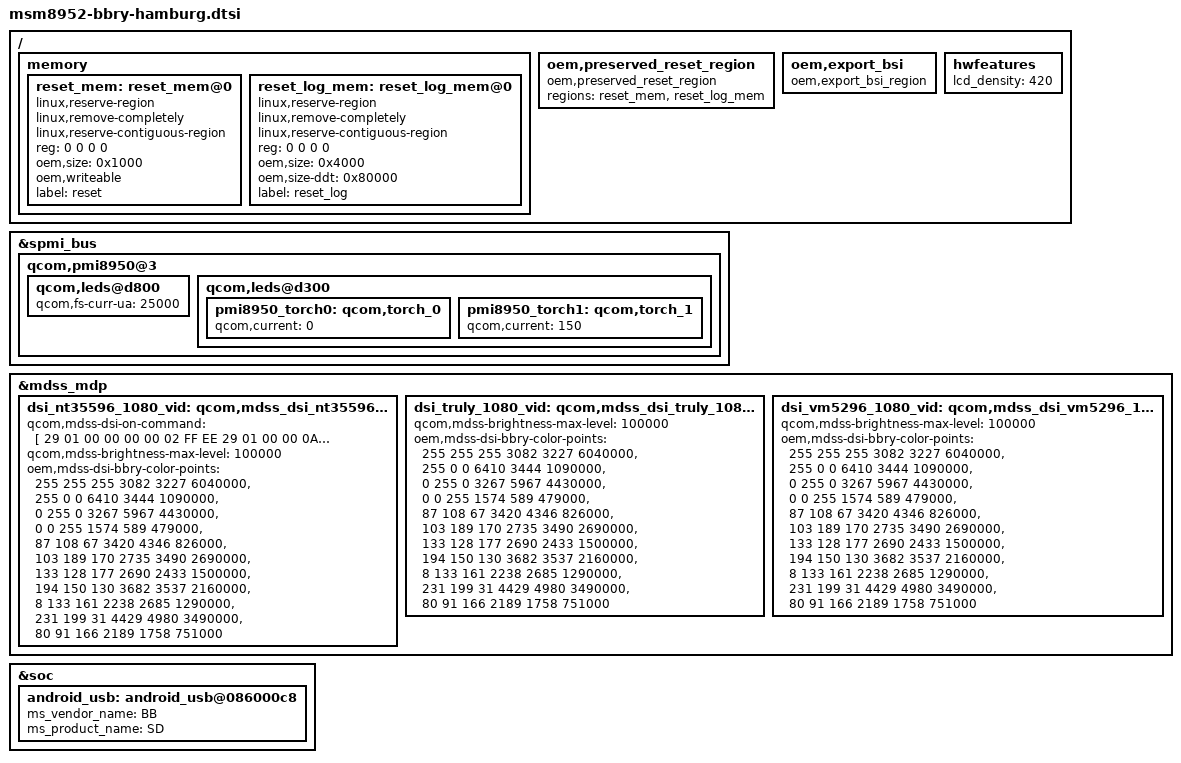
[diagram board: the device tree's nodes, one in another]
/* Copyright (C) 2016 BlackBerry Limited. All rights reserved.
 * Copyright (c) 2014, The Linux Foundation. All rights reserved.
 *
 * This program is free software; you can redistribute it and/or modify
 * it under the terms of the GNU General Public License version 2 and
 * only version 2 as published by the Free Software Foundation.
 *
 * This program is distributed in the hope that it will be useful,
 * but WITHOUT ANY WARRANTY; without even the implied warranty of
 * MERCHANTABILITY or FITNESS FOR A PARTICULAR PURPOSE.  See the
 * GNU General Public License for more details.
 */


/ {
	memory {
		reset_mem: reset_mem@0 {
			linux,reserve-region;
			linux,remove-completely;
			linux,reserve-contiguous-region;
			/*
			 * Bootloader take the address from the oem,size props
			 * and insert it here along with the address
			 */
			reg = <0 0 0 0>;
			oem,size = <0x1000>;
			oem,writeable;
			label = "reset";
		};

		reset_log_mem: reset_log_mem@0 {
			linux,reserve-region;
			linux,remove-completely;
			linux,reserve-contiguous-region;
			/*
			 * Bootloader take the address from the oem,size props
			 * and insert it here along with the address
			 */
			reg = <0 0 0 0>;
			oem,size = <0x4000>;
			/* If ddt is enabled, we reserve more memory */
			oem,size-ddt = <0x80000>;
			label = "reset_log";
		};
	};

	oem,preserved_reset_region {
		compatible = "oem,preserved_reset_region";
		regions = <&reset_mem &reset_log_mem> ;
	};

	oem,export_bsi {
		compatible = "oem,export_bsi_region", "oem,export_bsi";
	};
	hwfeatures {
		lcd_density = "420";
	};
};

&spmi_bus {
	qcom,pmi8950@3 {
		qcom,leds@d800 {
			qcom,fs-curr-ua = <25000>;
		};
		qcom,leds@d300 {
			pmi8950_torch0: qcom,torch_0 {
				qcom,current = <0>;
			};
			pmi8950_torch1: qcom,torch_1 {
				qcom,current = <150>;
			};
		};
	};
};

&mdss_mdp {
	dsi_nt35596_1080_vid: qcom,mdss_dsi_nt35596_1080p_video {
		qcom,mdss-dsi-on-command = [
		29 01 00 00 00 00 02 FF EE
		29 01 00 00 0A 00 02 18 40
		29 01 00 00 14 00 02 18 00
		29 01 00 00 00 00 02 FF 05
		29 01 00 00 00 00 02 FB 01
		29 01 00 00 00 00 02 C5 31
		29 01 00 00 00 00 02 FF EE
		29 01 00 00 00 00 02 7C 31
		29 01 00 00 00 00 02 FB 01
		29 01 00 00 00 00 02 FF 01
		29 01 00 00 00 00 02 30 0F
		29 01 00 00 00 00 02 00 01
		29 01 00 00 00 00 02 01 55
		29 01 00 00 00 00 02 02 40
		29 01 00 00 00 00 02 05 50
		29 01 00 00 00 00 02 06 4A
		29 01 00 00 00 00 02 07 29
		29 01 00 00 00 00 02 08 0C
		29 01 00 00 00 00 02 0B 87
		29 01 00 00 00 00 02 0C 87
		29 01 00 00 00 00 02 0E B0
		29 01 00 00 00 00 02 0F B3
		//sun zhangyang modify for Optimize the lcd based on HW begin, task1400997,2016.01.12
		#if 0
		29 01 00 00 00 00 02 11 20
		29 01 00 00 00 00 02 12 20
		#endif
		//sun zhangyang modify for Optimize the lcd based on HW end
		29 01 00 00 00 00 02 13 03
		29 01 00 00 00 00 02 14 4A
		29 01 00 00 00 00 02 15 12
		29 01 00 00 00 00 02 16 12
		29 01 00 00 00 00 02 18 00
		29 01 00 00 00 00 02 19 77
		29 01 00 00 00 00 02 1A 55
		29 01 00 00 00 00 02 1B 13
		29 01 00 00 00 00 02 1C 00
		29 01 00 00 00 00 02 1D 00
		29 01 00 00 00 00 02 1E 00
		29 01 00 00 00 00 02 1F 00
		29 01 00 00 00 00 02 58 82
		29 01 00 00 00 00 02 59 02
		29 01 00 00 00 00 02 5A 02
		29 01 00 00 00 00 02 5B 02
		29 01 00 00 00 00 02 5C 82
		29 01 00 00 00 00 02 5D 82
		29 01 00 00 00 00 02 5E 02
		29 01 00 00 00 00 02 5F 02
		29 01 00 00 00 00 02 72 31
		29 01 00 00 00 00 02 FB 01
		29 01 00 00 00 00 02 FF 05
        29 01 00 00 00 00 02 FB 01
		29 01 00 00 00 00 02 00 01
		29 01 00 00 00 00 02 01 0B
		29 01 00 00 00 00 02 02 0C
		29 01 00 00 00 00 02 03 09
		29 01 00 00 00 00 02 04 0A
		29 01 00 00 00 00 02 05 1A
		29 01 00 00 00 00 02 06 10
		29 01 00 00 00 00 02 07 00
		29 01 00 00 00 00 02 08 1A
		29 01 00 00 00 00 02 09 00
		29 01 00 00 00 00 02 0A 00
		29 01 00 00 00 00 02 0B 00
		29 01 00 00 00 00 02 0C 00
		29 01 00 00 00 00 02 0D 13
		29 01 00 00 00 00 02 0E 15
		29 01 00 00 00 00 02 0F 17
		29 01 00 00 00 00 02 10 01
		29 01 00 00 00 00 02 11 0B
		29 01 00 00 00 00 02 12 0C
		29 01 00 00 00 00 02 13 09
		29 01 00 00 00 00 02 14 0A
		29 01 00 00 00 00 02 15 1A
		29 01 00 00 00 00 02 16 10
		29 01 00 00 00 00 02 17 10
		29 01 00 00 00 00 02 18 1A
		29 01 00 00 00 00 02 19 00
		29 01 00 00 00 00 02 1A 00
		29 01 00 00 00 00 02 1B 00
		29 01 00 00 00 00 02 1C 00
		29 01 00 00 00 00 02 1D 13
		29 01 00 00 00 00 02 1E 15
		29 01 00 00 00 00 02 1F 17
		29 01 00 00 00 00 02 20 00
		29 01 00 00 00 00 02 21 01
		29 01 00 00 00 00 02 22 00
		29 01 00 00 00 00 02 23 40
		29 01 00 00 00 00 02 24 40
		29 01 00 00 00 00 02 25 6D
		29 01 00 00 00 00 02 29 D8
		29 01 00 00 00 00 02 2A 2A
		29 01 00 00 00 00 02 2B 00
		29 01 00 00 00 00 02 B6 89
		29 01 00 00 00 00 02 B7 14
		29 01 00 00 00 00 02 B8 05
		29 01 00 00 00 00 02 4B 04
		29 01 00 00 00 00 02 4C 11
		29 01 00 00 00 00 02 4D 10
		29 01 00 00 00 00 02 4E 01
		29 01 00 00 00 00 02 4F 01
		29 01 00 00 00 00 02 50 10
		29 01 00 00 00 00 02 51 00
		29 01 00 00 00 00 02 52 00
		29 01 00 00 00 00 02 53 08
		29 01 00 00 00 00 02 54 01
		29 01 00 00 00 00 02 55 6D
		29 01 00 00 00 00 02 5B 44
		29 01 00 00 00 00 02 5C 00
		29 01 00 00 00 00 02 5F 74
		29 01 00 00 00 00 02 60 75
		29 01 00 00 00 00 02 63 FF
		29 01 00 00 00 00 02 64 00
		29 01 00 00 00 00 02 67 04
		29 01 00 00 00 00 02 68 04
		29 01 00 00 00 00 02 6C 00
		29 01 00 00 00 00 02 7A 80
		29 01 00 00 00 00 02 7B 91
		29 01 00 00 00 00 02 7C D8
		29 01 00 00 00 00 02 7D 60
		29 01 00 00 00 00 02 7F 15
		29 01 00 00 00 00 02 80 00
		29 01 00 00 00 00 02 83 00
		29 01 00 00 00 00 02 93 08
		29 01 00 00 00 00 02 94 0A
		29 01 00 00 00 00 02 8A 00
		29 01 00 00 00 00 02 9B 0F
		//page selection cmd start
		29 01 00 00 00 00 02 FF 01
		29 01 00 00 00 00 02 FB 01
		//page selection cmd end
		//R(+) MCR cmd
		29 01 00 00 00 00 02 75 00
		29 01 00 00 00 00 02 76 03
		29 01 00 00 00 00 02 77 00
		29 01 00 00 00 00 02 78 0C
		29 01 00 00 00 00 02 79 00
		29 01 00 00 00 00 02 7A 3E
		29 01 00 00 00 00 02 7B 00
		29 01 00 00 00 00 02 7C 54
		29 01 00 00 00 00 02 7D 00
		29 01 00 00 00 00 02 7E 90
		29 01 00 00 00 00 02 7F 00
		29 01 00 00 00 00 02 80 AC
		29 01 00 00 00 00 02 81 00
		29 01 00 00 00 00 02 82 BD
		29 01 00 00 00 00 02 83 00
		29 01 00 00 00 00 02 84 CA
		29 01 00 00 00 00 02 85 00
		29 01 00 00 00 00 02 86 D9
		29 01 00 00 00 00 02 87 01
		29 01 00 00 00 00 02 88 0E
		29 01 00 00 00 00 02 89 01
		29 01 00 00 00 00 02 8A 31
		29 01 00 00 00 00 02 8B 01
		29 01 00 00 00 00 02 8C 6E
		29 01 00 00 00 00 02 8D 01
		29 01 00 00 00 00 02 8E 9F
		29 01 00 00 00 00 02 8F 01
		29 01 00 00 00 00 02 90 E7
		29 01 00 00 00 00 02 91 02
		29 01 00 00 00 00 02 92 21
		29 01 00 00 00 00 02 93 02
		29 01 00 00 00 00 02 94 24
		29 01 00 00 00 00 02 95 02
		29 01 00 00 00 00 02 96 57
		29 01 00 00 00 00 02 97 02
		29 01 00 00 00 00 02 98 8F
		29 01 00 00 00 00 02 99 02
		29 01 00 00 00 00 02 9A B4
		29 01 00 00 00 00 02 9B 02
		29 01 00 00 00 00 02 9C E7
		29 01 00 00 00 00 02 9D 03
		29 01 00 00 00 00 02 9E 09
		29 01 00 00 00 00 02 9F 03
		29 01 00 00 00 00 02 A0 39
		29 01 00 00 00 00 02 A2 03
		29 01 00 00 00 00 02 A3 48
		29 01 00 00 00 00 02 A4 03
		29 01 00 00 00 00 02 A5 59
		29 01 00 00 00 00 02 A6 03
		29 01 00 00 00 00 02 A7 6D
		29 01 00 00 00 00 02 A9 03
		29 01 00 00 00 00 02 AA 72
		29 01 00 00 00 00 02 AB 03
		29 01 00 00 00 00 02 AC 88
		29 01 00 00 00 00 02 AD 03
		29 01 00 00 00 00 02 AE A5
		29 01 00 00 00 00 02 AF 03
		29 01 00 00 00 00 02 B0 E8
		29 01 00 00 00 00 02 B1 03
		29 01 00 00 00 00 02 B2 F8
		//R(-) MCR cmd
		29 01 00 00 00 00 02 B3 00
		29 01 00 00 00 00 02 B4 03
		29 01 00 00 00 00 02 B5 00
		29 01 00 00 00 00 02 B6 0C
		29 01 00 00 00 00 02 B7 00
		29 01 00 00 00 00 02 B8 3E
		29 01 00 00 00 00 02 B9 00
		29 01 00 00 00 00 02 BA 54
		29 01 00 00 00 00 02 BB 00
		29 01 00 00 00 00 02 BC 90
		29 01 00 00 00 00 02 BD 00
		29 01 00 00 00 00 02 BE AC
		29 01 00 00 00 00 02 BF 00
		29 01 00 00 00 00 02 C0 BD
		29 01 00 00 00 00 02 C1 00
		29 01 00 00 00 00 02 C2 CA
		29 01 00 00 00 00 02 C3 00
		29 01 00 00 00 00 02 C4 D9
		29 01 00 00 00 00 02 C5 01
		29 01 00 00 00 00 02 C6 0E
		29 01 00 00 00 00 02 C7 01
		29 01 00 00 00 00 02 C8 31
		29 01 00 00 00 00 02 C9 01
		29 01 00 00 00 00 02 CA 6E
		29 01 00 00 00 00 02 CB 01
		29 01 00 00 00 00 02 CC 9F
		29 01 00 00 00 00 02 CD 01
		29 01 00 00 00 00 02 CE E7
		29 01 00 00 00 00 02 CF 02
		29 01 00 00 00 00 02 D0 21
		29 01 00 00 00 00 02 D1 02
		29 01 00 00 00 00 02 D2 24
		29 01 00 00 00 00 02 D3 02
		29 01 00 00 00 00 02 D4 57
		29 01 00 00 00 00 02 D5 02
		29 01 00 00 00 00 02 D6 8F
		29 01 00 00 00 00 02 D7 02
		29 01 00 00 00 00 02 D8 B4
		29 01 00 00 00 00 02 D9 02
		29 01 00 00 00 00 02 DA E7
		29 01 00 00 00 00 02 DB 03
		29 01 00 00 00 00 02 DC 09
		29 01 00 00 00 00 02 DD 03
		29 01 00 00 00 00 02 DE 39
		29 01 00 00 00 00 02 DF 03
		29 01 00 00 00 00 02 E0 48
		29 01 00 00 00 00 02 E1 03
		29 01 00 00 00 00 02 E2 59
		29 01 00 00 00 00 02 E3 03
		29 01 00 00 00 00 02 E4 6D
		29 01 00 00 00 00 02 E5 03
		29 01 00 00 00 00 02 E6 72
		29 01 00 00 00 00 02 E7 03
		29 01 00 00 00 00 02 E8 88
		29 01 00 00 00 00 02 E9 03
		29 01 00 00 00 00 02 EA A5
		29 01 00 00 00 00 02 EB 03
		29 01 00 00 00 00 02 EC E8
		29 01 00 00 00 00 02 ED 03
		29 01 00 00 00 00 02 EE F8
		//G(+) MCR cmd
		29 01 00 00 00 00 02 EF 00
		29 01 00 00 00 00 02 F0 03
		29 01 00 00 00 00 02 F1 00
		29 01 00 00 00 00 02 F2 0C
		29 01 00 00 00 00 02 F3 00
		29 01 00 00 00 00 02 F4 3E
		29 01 00 00 00 00 02 F5 00
		29 01 00 00 00 00 02 F6 54
		29 01 00 00 00 00 02 F7 00
		29 01 00 00 00 00 02 F8 90
		29 01 00 00 00 00 02 F9 00
		29 01 00 00 00 00 02 FA AC
		//page selection cmd start
		29 01 00 00 00 00 02 FF 02
		29 01 00 00 00 00 02 FB 01
		//page selection cmd end
		29 01 00 00 00 00 02 00 00
		29 01 00 00 00 00 02 01 BD
		29 01 00 00 00 00 02 02 00
		29 01 00 00 00 00 02 03 CA
		29 01 00 00 00 00 02 04 00
		29 01 00 00 00 00 02 05 D9
		29 01 00 00 00 00 02 06 01
		29 01 00 00 00 00 02 07 0E
		29 01 00 00 00 00 02 08 01
		29 01 00 00 00 00 02 09 31
		29 01 00 00 00 00 02 0A 01
		29 01 00 00 00 00 02 0B 6E
		29 01 00 00 00 00 02 0C 01
		29 01 00 00 00 00 02 0D 9F
		29 01 00 00 00 00 02 0E 01
		29 01 00 00 00 00 02 0F E7
		29 01 00 00 00 00 02 10 02
		29 01 00 00 00 00 02 11 21
		29 01 00 00 00 00 02 12 02
		29 01 00 00 00 00 02 13 24
		29 01 00 00 00 00 02 14 02
		29 01 00 00 00 00 02 15 57
		29 01 00 00 00 00 02 16 02
		29 01 00 00 00 00 02 17 8F
		29 01 00 00 00 00 02 18 02
		29 01 00 00 00 00 02 19 B4
		29 01 00 00 00 00 02 1A 02
		29 01 00 00 00 00 02 1B E7
		29 01 00 00 00 00 02 1C 03
		29 01 00 00 00 00 02 1D 09
		29 01 00 00 00 00 02 1E 03
		29 01 00 00 00 00 02 1F 39
		29 01 00 00 00 00 02 20 03
		29 01 00 00 00 00 02 21 48
		29 01 00 00 00 00 02 22 03
		29 01 00 00 00 00 02 23 59
		29 01 00 00 00 00 02 24 03
		29 01 00 00 00 00 02 25 6D
		29 01 00 00 00 00 02 26 03
		29 01 00 00 00 00 02 27 72
		29 01 00 00 00 00 02 28 03
		29 01 00 00 00 00 02 29 88
		29 01 00 00 00 00 02 2A 03
		29 01 00 00 00 00 02 2B A5
		29 01 00 00 00 00 02 2D 03
		29 01 00 00 00 00 02 2F E8
		29 01 00 00 00 00 02 30 03
		29 01 00 00 00 00 02 31 F8
		//G(-) MCR cmd
		29 01 00 00 00 00 02 32 00
		29 01 00 00 00 00 02 33 03
		29 01 00 00 00 00 02 34 00
		29 01 00 00 00 00 02 35 0C
		29 01 00 00 00 00 02 36 00
		29 01 00 00 00 00 02 37 3E
		29 01 00 00 00 00 02 38 00
		29 01 00 00 00 00 02 39 54
		29 01 00 00 00 00 02 3A 00
		29 01 00 00 00 00 02 3B 90
		29 01 00 00 00 00 02 3D 00
		29 01 00 00 00 00 02 3F AC
		29 01 00 00 00 00 02 40 00
		29 01 00 00 00 00 02 41 BD
		29 01 00 00 00 00 02 42 00
		29 01 00 00 00 00 02 43 CA
		29 01 00 00 00 00 02 44 00
		29 01 00 00 00 00 02 45 D9
		29 01 00 00 00 00 02 46 01
		29 01 00 00 00 00 02 47 0E
		29 01 00 00 00 00 02 48 01
		29 01 00 00 00 00 02 49 31
		29 01 00 00 00 00 02 4A 01
		29 01 00 00 00 00 02 4B 6E
		29 01 00 00 00 00 02 4C 01
		29 01 00 00 00 00 02 4D 9F
		29 01 00 00 00 00 02 4E 01
		29 01 00 00 00 00 02 4F E7
		29 01 00 00 00 00 02 50 02
		29 01 00 00 00 00 02 51 21
		29 01 00 00 00 00 02 52 02
		29 01 00 00 00 00 02 53 24
		29 01 00 00 00 00 02 54 02
		29 01 00 00 00 00 02 55 57
		29 01 00 00 00 00 02 56 02
		29 01 00 00 00 00 02 58 8F
		29 01 00 00 00 00 02 59 02
		29 01 00 00 00 00 02 5A B4
		29 01 00 00 00 00 02 5B 02
		29 01 00 00 00 00 02 5C E7
		29 01 00 00 00 00 02 5D 03
		29 01 00 00 00 00 02 5E 09
		29 01 00 00 00 00 02 5F 03
		29 01 00 00 00 00 02 60 39
		29 01 00 00 00 00 02 61 03
		29 01 00 00 00 00 02 62 48
		29 01 00 00 00 00 02 63 03
		29 01 00 00 00 00 02 64 59
		29 01 00 00 00 00 02 65 03
		29 01 00 00 00 00 02 66 6D
		29 01 00 00 00 00 02 67 03
		29 01 00 00 00 00 02 68 72
		29 01 00 00 00 00 02 69 03
		29 01 00 00 00 00 02 6A 88
		29 01 00 00 00 00 02 6B 03
		29 01 00 00 00 00 02 6C A5
		29 01 00 00 00 00 02 6D 03
		29 01 00 00 00 00 02 6E E8
		29 01 00 00 00 00 02 6F 03
		29 01 00 00 00 00 02 70 F8
		//B(+) MCR cmd
		29 01 00 00 00 00 02 71 00
		29 01 00 00 00 00 02 72 03
		29 01 00 00 00 00 02 73 00
		29 01 00 00 00 00 02 74 0C
		29 01 00 00 00 00 02 75 00
		29 01 00 00 00 00 02 76 3E
		29 01 00 00 00 00 02 77 00
		29 01 00 00 00 00 02 78 54
		29 01 00 00 00 00 02 79 00
		29 01 00 00 00 00 02 7A 90
		29 01 00 00 00 00 02 7B 00
		29 01 00 00 00 00 02 7C AC
		29 01 00 00 00 00 02 7D 00
		29 01 00 00 00 00 02 7E BD
		29 01 00 00 00 00 02 7F 00
		29 01 00 00 00 00 02 80 CA
		29 01 00 00 00 00 02 81 00
		29 01 00 00 00 00 02 82 D9
		29 01 00 00 00 00 02 83 01
		29 01 00 00 00 00 02 84 0E
		29 01 00 00 00 00 02 85 01
		29 01 00 00 00 00 02 86 31
		29 01 00 00 00 00 02 87 01
		29 01 00 00 00 00 02 88 6E
		29 01 00 00 00 00 02 89 01
		29 01 00 00 00 00 02 8A 9F
		29 01 00 00 00 00 02 8B 01
		29 01 00 00 00 00 02 8C E7
		29 01 00 00 00 00 02 8D 02
		29 01 00 00 00 00 02 8E 21
		29 01 00 00 00 00 02 8F 02
		29 01 00 00 00 00 02 90 24
		29 01 00 00 00 00 02 91 02
		29 01 00 00 00 00 02 92 57
		29 01 00 00 00 00 02 93 02
		29 01 00 00 00 00 02 94 8F
		29 01 00 00 00 00 02 95 02
		29 01 00 00 00 00 02 96 B4
		29 01 00 00 00 00 02 97 02
		29 01 00 00 00 00 02 98 E7
		29 01 00 00 00 00 02 99 03
		29 01 00 00 00 00 02 9A 09
		29 01 00 00 00 00 02 9B 03
		29 01 00 00 00 00 02 9C 39
		29 01 00 00 00 00 02 9D 03
		29 01 00 00 00 00 02 9E 48
		29 01 00 00 00 00 02 9F 03
		29 01 00 00 00 00 02 A0 59
		29 01 00 00 00 00 02 A2 03
		29 01 00 00 00 00 02 A3 6D
		29 01 00 00 00 00 02 A4 03
		29 01 00 00 00 00 02 A5 72
		29 01 00 00 00 00 02 A6 03
		29 01 00 00 00 00 02 A7 88
		29 01 00 00 00 00 02 A9 03
		29 01 00 00 00 00 02 AA A5
		29 01 00 00 00 00 02 AB 03
		29 01 00 00 00 00 02 AC E8
		29 01 00 00 00 00 02 AD 03
		29 01 00 00 00 00 02 AE F8
		//B(-) MCR cmd
		29 01 00 00 00 00 02 AF 00
		29 01 00 00 00 00 02 B0 03
		29 01 00 00 00 00 02 B1 00
		29 01 00 00 00 00 02 B2 0C
		29 01 00 00 00 00 02 B3 00
		29 01 00 00 00 00 02 B4 3E
		29 01 00 00 00 00 02 B5 00
		29 01 00 00 00 00 02 B6 54
		29 01 00 00 00 00 02 B7 00
		29 01 00 00 00 00 02 B8 90
		29 01 00 00 00 00 02 B9 00
		29 01 00 00 00 00 02 BA AC
		29 01 00 00 00 00 02 BB 00
		29 01 00 00 00 00 02 BC BD
		29 01 00 00 00 00 02 BD 00
		29 01 00 00 00 00 02 BE CA
		29 01 00 00 00 00 02 BF 00
		29 01 00 00 00 00 02 C0 D9
		29 01 00 00 00 00 02 C1 01
		29 01 00 00 00 00 02 C2 0E
		29 01 00 00 00 00 02 C3 01
		29 01 00 00 00 00 02 C4 31
		29 01 00 00 00 00 02 C5 01
		29 01 00 00 00 00 02 C6 6E
		29 01 00 00 00 00 02 C7 01
		29 01 00 00 00 00 02 C8 9F
		29 01 00 00 00 00 02 C9 01
		29 01 00 00 00 00 02 CA E7
		29 01 00 00 00 00 02 CB 02
		29 01 00 00 00 00 02 CC 21
		29 01 00 00 00 00 02 CD 02
		29 01 00 00 00 00 02 CE 24
		29 01 00 00 00 00 02 CF 02
		29 01 00 00 00 00 02 D0 57
		29 01 00 00 00 00 02 D1 02
		29 01 00 00 00 00 02 D2 8F
		29 01 00 00 00 00 02 D3 02
		29 01 00 00 00 00 02 D4 B4
		29 01 00 00 00 00 02 D5 02
		29 01 00 00 00 00 02 D6 E7
		29 01 00 00 00 00 02 D7 03
		29 01 00 00 00 00 02 D8 09
		29 01 00 00 00 00 02 D9 03
		29 01 00 00 00 00 02 DA 39
		29 01 00 00 00 00 02 DB 03
		29 01 00 00 00 00 02 DC 48
		29 01 00 00 00 00 02 DD 03
		29 01 00 00 00 00 02 DE 59
		29 01 00 00 00 00 02 DF 03
		29 01 00 00 00 00 02 E0 6D
		29 01 00 00 00 00 02 E1 03
		29 01 00 00 00 00 02 E2 72
		29 01 00 00 00 00 02 E3 03
		29 01 00 00 00 00 02 E4 88
		29 01 00 00 00 00 02 E5 03
		29 01 00 00 00 00 02 E6 A5
		29 01 00 00 00 00 02 E7 03
		29 01 00 00 00 00 02 E8 E8
		29 01 00 00 00 00 02 E9 03
		29 01 00 00 00 00 02 EA F8
		//gamma end
		29 01 00 00 00 00 02 FF 05
		29 01 00 00 00 00 02 FB 01
		29 01 00 00 00 00 02 E7 80
		29 01 00 00 00 00 02 FB 01
		29 01 00 00 00 00 02 EC 00
		29 01 00 00 00 00 02 FF 00
		29 01 00 00 00 00 02 D3 06  //06
		29 01 00 00 00 00 02 D4 04   //04
		29 01 00 00 00 00 02 FF 00
		29 01 00 00 00 00 02 35 00
		29 01 00 00 78 00 02 11 00  // TCT-SH jhyu case905630_decrease lcd sleep out init time 12-7-2015
		29 01 00 00 00 00 02 55 80  // BBRY: enable colour enhancement
		29 01 00 00 14 00 02 29 00];// TCT-SH jhyu case905630_decrease lcd display on time 12-7-2015
		qcom,mdss-brightness-max-level = <100000>;

		/* Values provided by Display Hardware team, specific to this
		  * panel used for color correction.
		  * The first 4 values should be white (R,B and G=255), red (R=255,
		  * G and B=0), green (G=255, R and B=0) and blue (B=255, R and
		  * G=0), in that order. The x,y and Y values are measured by the
		  * Display HW team and are multiplied by 10000 to covert them to
		  * integers.  They are converted back to floating point when used
		  * in color management calculations.
		  *                                R    G    B    x       y     Y */

		oem,mdss-dsi-bbry-color-points = <255  255  255     3082    3227    6040000>,
									<255  0    0    6410    3444    1090000>,
									<0    255  0    3267    5967    4430000>,
									<0    0    255  1574    589     479000>,
									<87   108  67   3420    4346    826000>,
									<103  189  170  2735    3490    2690000>,
									<133  128  177  2690    2433    1500000>,
									<194  150  130  3682    3537    2160000>,
									<8    133  161  2238    2685    1290000>,
									<231  199  31   4429    4980    3490000>,
									<80   91   166  2189    1758    751000>;
	};

	dsi_truly_1080_vid: qcom,mdss_dsi_truly_1080p_video {
		qcom,mdss-brightness-max-level = <100000>;
		oem,mdss-dsi-bbry-color-points = <255  255  255     3082    3227    6040000>,
									<255  0    0    6410    3444    1090000>,
									<0    255  0    3267    5967    4430000>,
									<0    0    255  1574    589     479000>,
									<87   108  67   3420    4346    826000>,
									<103  189  170  2735    3490    2690000>,
									<133  128  177  2690    2433    1500000>,
									<194  150  130  3682    3537    2160000>,
									<8    133  161  2238    2685    1290000>,
									<231  199  31   4429    4980    3490000>,
									<80   91   166  2189    1758    751000>;
	};

	dsi_vm5296_1080_vid: qcom,mdss_dsi_vm5296_1080p_video {
		qcom,mdss-brightness-max-level = <100000>;
		oem,mdss-dsi-bbry-color-points = <255  255  255     3082    3227    6040000>,
									<255  0    0    6410    3444    1090000>,
									<0    255  0    3267    5967    4430000>,
									<0    0    255  1574    589     479000>,
									<87   108  67   3420    4346    826000>,
									<103  189  170  2735    3490    2690000>,
									<133  128  177  2690    2433    1500000>,
									<194  150  130  3682    3537    2160000>,
									<8    133  161  2238    2685    1290000>,
									<231  199  31   4429    4980    3490000>,
									<80   91   166  2189    1758    751000>;
	};
};

&soc {
	android_usb: android_usb@086000c8 {
		ms_vendor_name = "BB";    /* Mass Storage device vendor name:8 characters or less */
		ms_product_name = "SD";   /* Mass Storage device product name:16 characters or less */
	};
};

